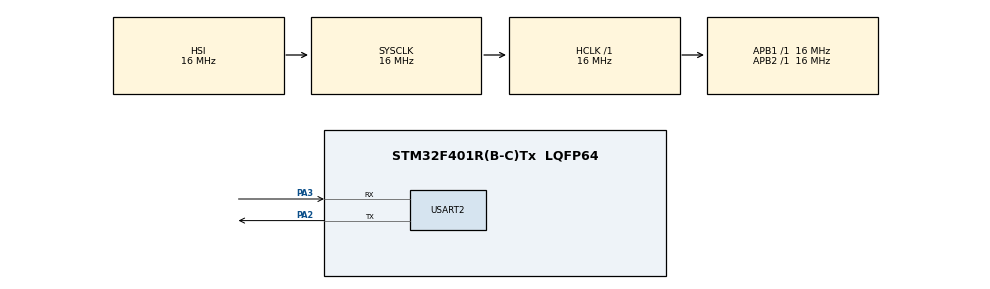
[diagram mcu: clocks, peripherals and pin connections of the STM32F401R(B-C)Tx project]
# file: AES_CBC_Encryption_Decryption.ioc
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Mcu.Family=STM32F4
Mcu.Name=STM32F401R(B-C)Tx
Mcu.Package=LQFP64
NVIC.PriorityGroup=NVIC_PRIORITYGROUP_4
PA2.Mode=Asynchronous
PA2.Signal=USART2_TX
PA3.Mode=Asynchronous
PA3.Signal=USART2_RX
ProjectManager.HeapSize=0x200
ProjectManager.StackSize=0x400
ProjectManager.TargetToolchain=STM32CubeIDE
RCC.AHBFreq_Value=16000000
RCC.APB1Freq_Value=16000000
RCC.APB2Freq_Value=16000000
RCC.CortexFreq_Value=16000000
RCC.HSE_VALUE=25000000
RCC.HSI_VALUE=16000000
RCC.LSE_VALUE=32768
RCC.SYSCLKFreq_VALUE=16000000
RCC.VCOOutputFreq_Value=192000000
USART2.VirtualMode=VM_ASYNC
VP_wolfSSL.I-CUBE-wolfSSL_VS_wolfSSLJjwolfSSL_5.7.2_5.7.2.Mode=wolfSSLJjwolfSSL
board=custom
wolfSSL.I-CUBE-wolfSSL.5.7.2.WOLF_CONF_AESCBC=1
wolfSSL.I-CUBE-wolfSSL.5.7.2.WOLF_CONF_AESGCM=0
wolfSSL.I-CUBE-wolfSSL.5.7.2.wolfSSLCcwolfSSLJjwolfCryptJjCore=true

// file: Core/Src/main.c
/* USER CODE BEGIN Header */
/**
  ******************************************************************************
  * @file           : main.c
  * @brief          : Main program body
  ******************************************************************************
  * @attention
  *
  * <h2><center>&copy; Copyright (c) 2024 STMicroelectronics.
  * All rights reserved.</center></h2>
  *
  * This software component is licensed by ST under Ultimate Liberty license
  * SLA0044, the "License"; You may not use this file except in compliance with
  * the License. You may obtain a copy of the License at:
  *                             www.st.com/SLA0044
  *
  ******************************************************************************
  */
/* USER CODE END Header */
#include "main.h"
#include "usart.h"
#include "gpio.h"

/* USER CODE BEGIN Includes */

#include "../Middlewares/Third_Party/wolfSSL_wolfSSL_wolfSSL/wolfssl/wolfssl/wolfcrypt/rsa.h"
#include "../Middlewares/Third_Party/wolfSSL_wolfSSL_wolfSSL/wolfssl/wolfssl/wolfcrypt/aes.h"

#include "../Middlewares/Third_Party/wolfSSL_wolfSSL_wolfSSL/wolfssl/wolfssl/wolfcrypt/cryptocb.h"
#include "../Middlewares/Third_Party/wolfSSL_wolfSSL_wolfSSL/wolfssl/wolfssl/wolfcrypt/cmac.h"
/* USER CODE END Includes */

/* USER CODE BEGIN PD */
#if 1	/* AES 256 */   // CBC Mode
	#define AES_128_KEY_SIZE 16
	#define AES_128_IV_SIZE  16

	Aes enc;  // Encryption Workspace algorithms
	Aes dec;  // Decryption Workspace algorithms

	void* hint = NULL;
	int devId = INVALID_DEVID;

	int EncRet = 0;
	uint8_t AES_key[AES_128_KEY_SIZE] = {0x00, 0x01, 0x02, 0x03, 0x04, 0x05, 0x06, 0x07, 0x00, 0x01, 0x02, 0x03, 0x04, 0x05, 0x06, 0x07};
	uint8_t iv[AES_128_IV_SIZE]  = {0x0, 0x1, 0x02, 0x03, 0x04, 0x05, 0x06, 0x07, 0x00, 0x01, 0x02, 0x03, 0x04, 0x05, 0x06, 0x07};

	// Multiple of 16 bytes
	uint8_t UART_msg[AES_BLOCK_SIZE] = {0x0, 0x1, 0x02, 0x03, 0x04, 0x05, 0x06, 0x07, 0x00, 0x01, 0x02, 0x03, 0x04, 0x05, 0x06, 0x07};
	uint8_t UART_msgCipher[AES_BLOCK_SIZE] = {0x00}; // Contain encryption UART_msg
	uint8_t UART_msgPlain [AES_BLOCK_SIZE] = {0x00}; // contain decryption UART_msgCipher

	int DecRet = 0;
#endif

#if 0  /* RSA */

#endif

#if 0 /* CMAC */

#endif

/* USER CODE END PD */

void SystemClock_Config(void);

int main(void)
{

  /* MCU Configuration--------------------------------------------------------*/

  /* Reset of all peripherals, Initializes the Flash interface and the Systick. */
  HAL_Init();

  /* Configure the system clock */
  SystemClock_Config();

  /* Initialize all configured peripherals */
  MX_GPIO_Init();
  MX_USART2_UART_Init();
  /* USER CODE BEGIN 2 */
#if 1  /* AES */

    /*  using wolfssl
     * https://www.wolfssl.com/
     * https://www.wolfssl.com/documentation/manuals/wolfssl/group__AES.html
     * */

  EncRet = wc_AesInit(&enc, hint, devId);
    if(EncRet == 0){
    	EncRet |= wc_AesSetKey(&enc, AES_key, AES_BLOCK_SIZE, iv, AES_ENCRYPTION);
    	if(EncRet == 0){
    		EncRet |= wc_AesSetIV(&enc, iv);
    	}
			if(EncRet == 0){
				EncRet = wc_AesCbcEncrypt(&enc, UART_msgCipher, UART_msg, sizeof(UART_msg));
				 if (EncRet == 0){
						 EncRet = wc_AesInit(&dec, hint, devId);
						 EncRet |= wc_AesSetKey(&dec, AES_key, AES_BLOCK_SIZE, iv, AES_DECRYPTION);
						 EncRet |= wc_AesSetIV(&dec, iv);
				 }
					 if (EncRet == 0){
						 EncRet |= wc_AesCbcDecrypt(&dec, UART_msgPlain, UART_msgCipher, sizeof(UART_msgCipher));
							 if (EncRet == 0) {
							  DecRet = 1;
				    }
     	     }

        }

    }

#endif

#if 0  /* RSA */

#endif

#if 0  /* MAC */

#endif

  /* USER CODE END 2 */

  /* Infinite loop */
  while (1)
  {

  }
}

void SystemClock_Config(void)
{
  RCC_OscInitTypeDef RCC_OscInitStruct = {0};
  RCC_ClkInitTypeDef RCC_ClkInitStruct = {0};

  /** Configure the main internal regulator output voltage
  */
  __HAL_RCC_PWR_CLK_ENABLE();
  __HAL_PWR_VOLTAGESCALING_CONFIG(PWR_REGULATOR_VOLTAGE_SCALE2);
  /** Initializes the RCC Oscillators according to the specified parameters
  * in the RCC_OscInitTypeDef structure.
  */
  RCC_OscInitStruct.OscillatorType = RCC_OSCILLATORTYPE_HSI;
  RCC_OscInitStruct.HSIState = RCC_HSI_ON;
  RCC_OscInitStruct.HSICalibrationValue = RCC_HSICALIBRATION_DEFAULT;
  RCC_OscInitStruct.PLL.PLLState = RCC_PLL_NONE;
  if (HAL_RCC_OscConfig(&RCC_OscInitStruct) != HAL_OK)
  {
    Error_Handler();
  }
  /** Initializes the CPU, AHB and APB buses clocks
  */
  RCC_ClkInitStruct.ClockType = RCC_CLOCKTYPE_HCLK|RCC_CLOCKTYPE_SYSCLK
                              |RCC_CLOCKTYPE_PCLK1|RCC_CLOCKTYPE_PCLK2;
  RCC_ClkInitStruct.SYSCLKSource = RCC_SYSCLKSOURCE_HSI;
  RCC_ClkInitStruct.AHBCLKDivider = RCC_SYSCLK_DIV1;
  RCC_ClkInitStruct.APB1CLKDivider = RCC_HCLK_DIV1;
  RCC_ClkInitStruct.APB2CLKDivider = RCC_HCLK_DIV1;

  if (HAL_RCC_ClockConfig(&RCC_ClkInitStruct, FLASH_LATENCY_0) != HAL_OK)
  {
    Error_Handler();
  }
}

void Error_Handler(void)
{
  __disable_irq();
  while (1)
  {
  }
}

/************************ (C) COPYRIGHT STMicroelectronics *****END OF FILE****/
